# TLE984x register map
Vendor: Infineon Technologies AG; File version: 1.6
CPU: CM0 r0p0, little endian, no MPU, no FPU, 2 interrupt priority bits
Registers are 32-bit, read-write, no defined reset value unless marked. A register's access mark holds for its fields unless they carry their own. Offsets are from the block's base; [hi:lo] are bit positions; 'fields as' and 'values as' point back to an identical list.

## HS
Base 0x40024000
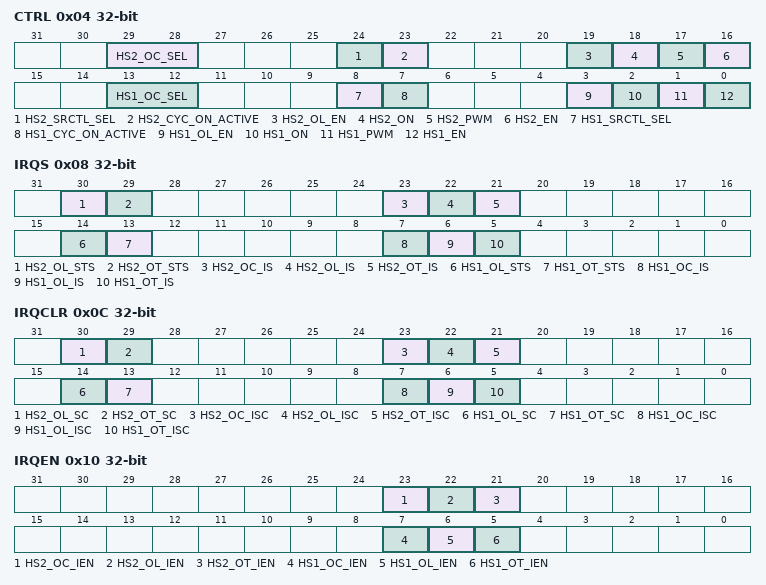
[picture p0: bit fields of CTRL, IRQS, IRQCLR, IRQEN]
0x04 CTRL — High Side Driver Control
  [29:28] HS2_OC_SEL — High Side 2 Overcurrent Threshold Selection
    0=IOCTH0 (25 mA min.); 1=IOCTH1 (50 mA min.); 2=IOCTH2 (100 mA min.); 3=IOCTH3 (150 mA min.)
  [24] HS2_SRCTL_SEL — High Side 2 Slew Rate Control select
    0=Slew Rate 10V/us is enabled; 1=Slew Rate 2 (Slew Rate 30V/us is enabled)
  [23] HS2_CYC_ON_ACTIVE — High Side 2 Cyclic ON Driver
    0=OFF (Cyclic ON Driver OFF); 1=ON (Cyclic ON Driver ON)
  [19] HS2_OL_EN — High Side 2 Open Load Detection Enable
    0=DISABLE (disable open load detection); 1=ENABLE (enable open load detection)
  [18] HS2_ON — High Side 2 On
    0=OFF (HS driver off); 1=ON (HS driver on)
  [17] HS2_PWM — High Side 2 PWM Enable
    0=DISABLE (disables control by PWM input); 1=ENABLE (enables control by PWM input)
  [16] HS2_EN — High Side 2 Enable
    0=DISABLE (HS circuit power off); 1=ENABLE (HS circuit power on)
  [13:12] HS1_OC_SEL — High Side 1 Overcurrent Threshold Selection
    values as HS2_OC_SEL
  [8] HS1_SRCTL_SEL — High Side 1 Slew Rate Control select
    values as HS2_SRCTL_SEL
  [7] HS1_CYC_ON_ACTIVE — High Side 1 Cyclic ON Driver
    0=OFF (Cyclic ON Driver OFF); 1=ON (Cyclic ON Driver ON)
  [3] HS1_OL_EN — High Side 1 Open Load Detection Enable
    values as HS2_OL_EN
  [2] HS1_ON — High Side 1 On
    0=OFF (HS driver off); 1=ON (HS driver on)
  [1] HS1_PWM — High Side 1 PWM Enable
    values as HS2_PWM
  [0] HS1_EN — High Side 1 Enable
    values as HS2_EN
0x08 IRQS — High Side Driver Interrupt Status
  [30] HS2_OL_STS — High Side 2 Open Load Interrupt Status
    0=no open load Condition occurred; 1=open load occurred; switch is not automatically shutdown. Write sets status.
  [29] HS2_OT_STS — High Side 2 Overtemperature Status
    0=no overtemperature occurred; 1=overtemperature occurred; switch is automatically shutdown. Write sets status.
  [23] HS2_OC_IS — High Side 2 Overcurrent Interrupt Status
    0=no overcurrent Condition occurred; 1=overcurrent occurred; switch is automatically shutdown. Write sets status.
  [22] HS2_OL_IS — High Side 2 Open Load Interrupt Status
    0=NORMAL (normal load); 1=OPEN LOAD (open load detected, write sets status)
  [21] HS2_OT_IS — High Side 2 Overtemperature Interrupt Status
    0=no overtemperature occurred; 1=overtemperature occurred; switch is automatically shutdown. Write sets status
  [14] HS1_OL_STS — High Side 1 Open Load Interrupt Status
    values as HS2_OL_STS
  [13] HS1_OT_STS — High Side 1 Overtemperature Status
    values as HS2_OT_STS
  [7] HS1_OC_IS — High Side 1 Overcurrent Interrupt Status
    values as HS2_OC_IS
  [6] HS1_OL_IS — High Side 1 Open Load Interrupt Status
    values as HS2_OL_IS
  [5] HS1_OT_IS — High Side 1 Overtemperature Interrupt Status
    values as HS2_OT_IS
0x0C IRQCLR wo — High Side Driver Interrupt Status Clear Register
  [all] fields
    0=no Clear; 1=Clear
  [30] HS2_OL_SC — High Side 2 Open Load Status Clear
  [29] HS2_OT_SC — High Side 2 Overtemperature Status Clear
  [23] HS2_OC_ISC — High Side 2 Overcurrent Interrupt Status Clear
  [22] HS2_OL_ISC — High Side 2 Open Load Interrupt Status Clear
  [21] HS2_OT_ISC — High Side 2 Overtemperature Interrupt Status Clear
  [14] HS1_OL_SC — High Side 1 Open Load Status Clear
  [13] HS1_OT_SC — High Side 1 Overtemperature Status Clear
  [7] HS1_OC_ISC — High Side 1 Overcurrent Interrupt Status Clear
  [6] HS1_OL_ISC — High Side 1 Open Load Interrupt Status Clear
  [5] HS1_OT_ISC — High Side 1 Overtemperature Interrupt Status Clear
0x10 IRQEN — High Side Driver Interrupt Enable Register
  [23] HS2_OC_IEN — High Side 2 Overcurrent interrupt enable
    0=disable; 1=enable
  [22] HS2_OL_IEN — High Side 2 Open Load interrupt enable
    0=disable; 1=enable
  [21] HS2_OT_IEN — High Side 2 Overtemperature interrupt enable
    0=disabled; 1=enable
  [7] HS1_OC_IEN — High Side 1 Overcurrent interrupt enable
    0=disable; 1=enable
  [6] HS1_OL_IEN — High Side 1 Open Load interrupt enable
    0=disable; 1=enable
  [5] HS1_OT_IEN — High Side 1 Overtemperature interrupt enable
    0=disabled; 1=enable
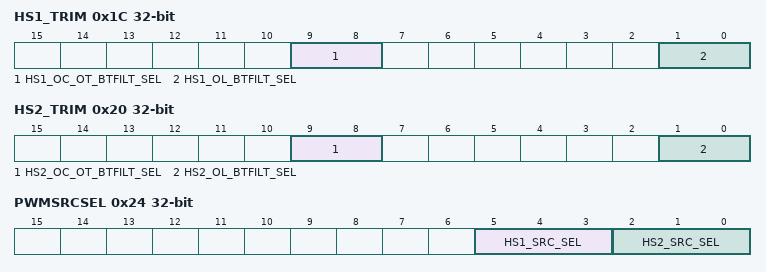
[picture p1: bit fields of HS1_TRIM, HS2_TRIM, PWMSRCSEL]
0x1C HS1_TRIM — High Side Driver 1 TRIM
  [9:8] HS1_OC_OT_BTFILT_SEL — Blanking Time Filter Select for HS1 Overcurrent / Overtemperature Detection
    0=4 us filter time; 1=8 us filter time; 2=16 us filter time; 3=32 us filter time
  [1:0] HS1_OL_BTFILT_SEL — Blanking Time Filter Select for HS1 Open Load Detection
    0=2_us (4 us filter time); 1=4_us (8 us filter time); 2=8_us (16 us filter time); 3=16_us (32 us filter time)
0x20 HS2_TRIM — High Side Driver 2 TRIM
  [9:8] HS2_OC_OT_BTFILT_SEL — Blanking Time Filter Select for HS2 Overcurrent / Overtemperature Detection
    values as HS1_TRIM.HS1_OC_OT_BTFILT_SEL
  [1:0] HS2_OL_BTFILT_SEL — Blanking Time Filter Select for HS2 Open Load Detection
    values as HS1_TRIM.HS1_OL_BTFILT_SEL
0x24 PWMSRCSEL — High Side PWM Source Selection Register
  [5:3] HS1_SRC_SEL — HS1 PWM Source Selection
    0=CC60 (PWM output of CCU6); 1=CC61 (PWM output of CCU6); 2=CC62 (PWM output of CCU6); 3=COUT60 (PWM output of CCU6); 4=COUT61 (PWM output of CCU6); 5=COUT62 (PWM output of CCU6); 6=T3OUT (PWM output of GPT12)
  [2:0] HS2_SRC_SEL — HS2 PWM Source Selection
    values as HS1_SRC_SEL
